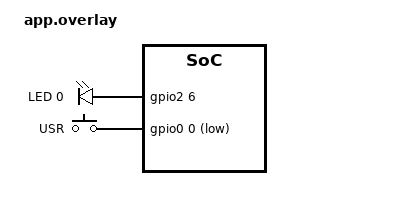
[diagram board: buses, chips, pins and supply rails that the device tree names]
/ {
	leds {
		compatible = "gpio-leds";

		led0: led_0 {
			gpios = <&gpio2 6 GPIO_ACTIVE_HIGH>;
			label = "LED 0";
		};
	};

	buttons: buttons {
		compatible = "gpio-keys";

		usr_btn: usr-btn {
			gpios = <&gpio0 0 (GPIO_PULL_UP | GPIO_ACTIVE_LOW)>;
			label = "USR";
			zephyr,code = <INPUT_KEY_ENTER>;
		};
	};

	aliases {
		led0 = &led0;
		buttons = &buttons;
		sw0 = &usr_btn;
	};
};
